AUTOSAR XML (schema 314)
package /ComponentType
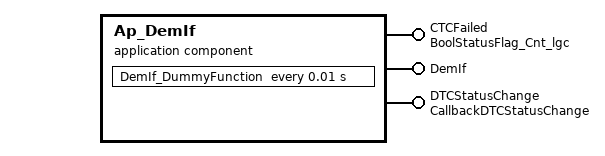
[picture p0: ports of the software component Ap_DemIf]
  application software component type Ap_DemIf
    provide port CTCFailed: unqueued-sender-com-spec{data-element=Cnt_lgc, can-invalidate=false, init-value=D_FALSE_CNT_LGC}, provided-interface=BoolStatusFlag_Cnt_lgc
    provide port DemIf: provided-interface=DemIf
      provided-com-specs:
        operation=DemShutdown, queue-length=1
        operation=RestartDem, queue-length=1
        operation=SetEventStatus, queue-length=1
        operation=SetOperationCycleState, queue-length=1
    provide port DTCStatusChange: server-com-spec{operation=DTCStatusChanged, queue-length=1}, provided-interface=CallbackDTCStatusChange
  internal behavior Ap_DemIf_InternalBehavior: component=Ap_DemIf
    operation invoked event OIT_DemIf_DemShutdown_DemIf_DemShutdown: start-on-event=DemIf_DemShutdown, operation=DemIf.DemShutdown
    operation invoked event OIT_DemIf_DTCStatusChanged_DTCStatusChange_DTCStatusChanged: start-on-event=DemIf_DTCStatusChanged, operation=DTCStatusChange.DTCStatusChanged
    timing event TMT_DemIf_DummyFunction: start-on-event=DemIf_DummyFunction, period=0.01
    operation invoked event OIT_DemIf_RestartDem_DemIf_RestartDem: start-on-event=DemIf_RestartDem, operation=DemIf.RestartDem
    operation invoked event OIT_DemIf_SetEventStatus_DemIf_SetEventStatus: start-on-event=DemIf_SetEventStatus, operation=DemIf.SetEventStatus
    operation invoked event OIT_DemIf_SetOperationCycleState_DemIf_SetOperationCycleState: start-on-event=DemIf_SetOperationCycleState, operation=DemIf.SetOperationCycleState
    port-api-options:
      enable-take-address=false, indirect-api=false, port=CTCFailed
      enable-take-address=false, indirect-api=false, port=DemIf
      enable-take-address=false, indirect-api=false, port=DTCStatusChange
    6 x runnable:
      DemIf_DemShutdown: can-be-invoked-concurrently=true
      DemIf_DTCStatusChanged
        data send point SEND_CTCFailed_Cnt_lgc: data-element=CTCFailed.Cnt_lgc
      DemIf_DummyFunction
      DemIf_RestartDem: can-be-invoked-concurrently=true
      DemIf_SetEventStatus: can-be-invoked-concurrently=true
      DemIf_SetOperationCycleState: can-be-invoked-concurrently=true
  swc implementation Ap_DemIf_Implementation: behavior=Ap_DemIf_InternalBehavior
    code-descriptors:
      code Code: type=SRC
